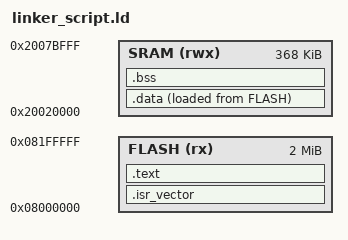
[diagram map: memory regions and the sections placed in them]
ENTRY(reset_handler)

MEMORY
{
  SRAM (rwx): ORIGIN = 0x20020000, LENGTH = 368K
  FLASH (rx): ORIGIN = 0x08000000, LENGTH = 2M
}

SECTIONS
{
  .isr_vector :
  {
    KEEP(*(.isr_vector))
  } >FLASH

  .text :
  {
    . = ALIGN(4);
		
    *(.text)
    *(.rodata)
		
    . = ALIGN(4);
    _etext = .;
  } >FLASH

  .data :
  {
    . = ALIGN(4);
    _sdata = .;
		
    *(.data)

    . = ALIGN(4);
    _edata = .;
  } >SRAM AT> FLASH

  .bss :
  {
    . = ALIGN(4);
    _sbss = .;
		
    *(.bss)
		
    . = ALIGN(4);
    _ebss = .;
  } >SRAM
}

